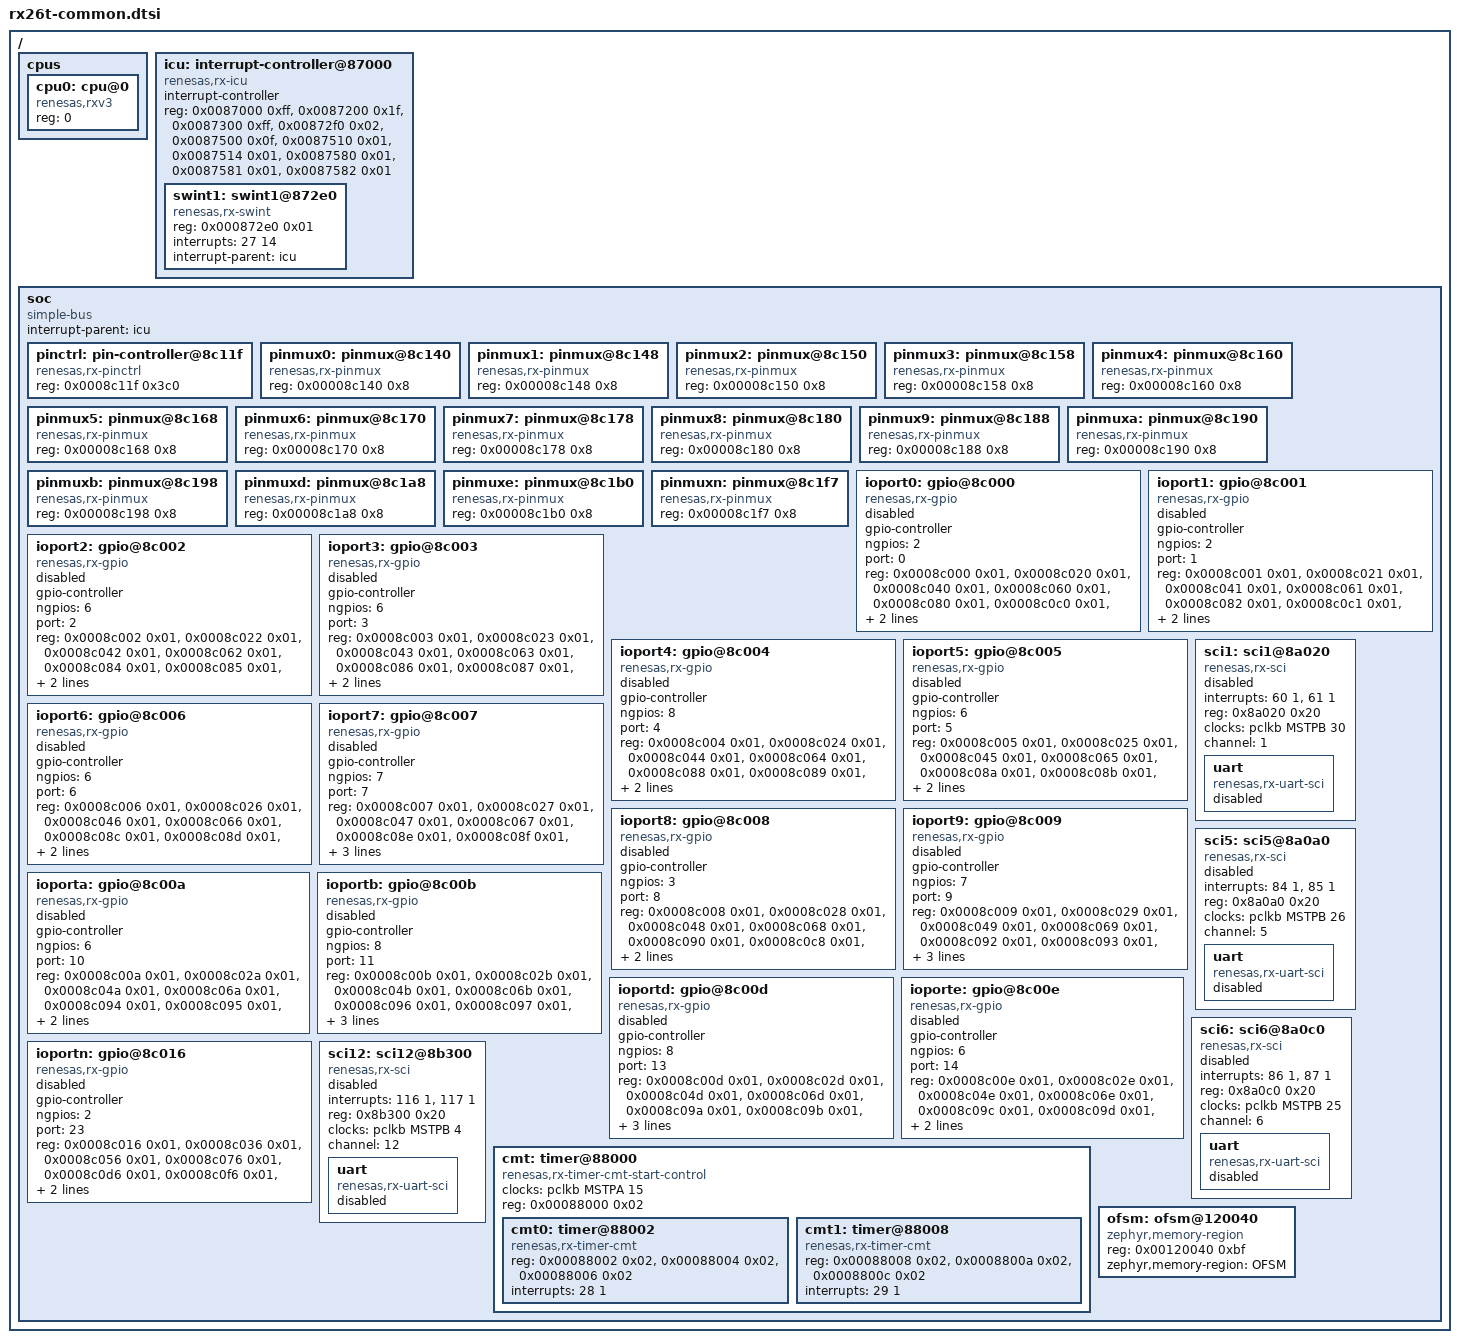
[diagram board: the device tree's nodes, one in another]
/*
 * Copyright (c) 2025 Renesas Electronics Corporation
 *
 * SPDX-License-Identifier: Apache-2.0
 */

/*
 * common device tree elements of all (currently supported) RX MCUs
 */

#include <mem.h>
#include <zephyr/dt-bindings/clock/rx_clock.h>
#include <zephyr/dt-bindings/pinctrl/renesas/pinctrl-rx.h>

/ {
	#address-cells = <1>;
	#size-cells = <1>;

	cpus {
		#address-cells = <1>;
		#size-cells = <0>;

		cpu0: cpu@0 {
			compatible = "renesas,rxv3";
			device_type = "cpu";
			reg = <0>;
			status = "okay";
		};
	};

	icu: interrupt-controller@87000 {
		#interrupt-cells = <2>;
		#address-cells = <1>;
		#size-cells = <1>;
		compatible = "renesas,rx-icu";
		interrupt-controller;
		reg = <0x0087000 0xff>,
		      <0x0087200 0x1f>,
		      <0x0087300 0xff>,
		      <0x00872f0 0x02>,
		      <0x0087500 0x0f>,
		      <0x0087510 0x01>,
		      <0x0087514 0x01>,
		      <0x0087580 0x01>,
		      <0x0087581 0x01>,
		      <0x0087582 0x01>;
		reg-names = "IR", "IER", "IPR", "FIR", "IRQCR", "IRQFLTE", "IRQFLTC0", "NMISR",
			    "NMIER", "NMICLR";

		swint1: swint1@872e0 {
			compatible = "renesas,rx-swint";
			reg = <0x000872e0 0x01>;
			interrupts = <27 14>;
			interrupt-parent = <&icu>;
			status = "okay";
		};
	};

	soc {
		#address-cells = <1>;
		#size-cells = <1>;
		device_type = "soc";
		compatible = "simple-bus";
		interrupt-parent = <&icu>;

		pinctrl: pin-controller@8c11f {
			compatible = "renesas,rx-pinctrl";
			reg = <0x0008c11f 0x3c0>;
			status = "okay";
		};

		pinmux0: pinmux@8c140 {
			compatible = "renesas,rx-pinmux";
			#pinmux-cells = <2>;
			reg = <0x00008c140 0x8>;
			status = "okay";
		};

		pinmux1: pinmux@8c148 {
			compatible = "renesas,rx-pinmux";
			#pinmux-cells = <2>;
			reg = <0x00008c148 0x8>;
			status = "okay";
		};

		pinmux2: pinmux@8c150 {
			compatible = "renesas,rx-pinmux";
			#pinmux-cells = <2>;
			reg = <0x00008c150 0x8>;
			status = "okay";
		};

		pinmux3: pinmux@8c158 {
			compatible = "renesas,rx-pinmux";
			#pinmux-cells = <2>;
			reg = <0x00008c158 0x8>;
			status = "okay";
		};

		pinmux4: pinmux@8c160 {
			compatible = "renesas,rx-pinmux";
			#pinmux-cells = <2>;
			reg = <0x00008c160 0x8>;
			status = "okay";
		};

		pinmux5: pinmux@8c168 {
			compatible = "renesas,rx-pinmux";
			#pinmux-cells = <2>;
			reg = <0x00008c168 0x8>;
			status = "okay";
		};

		pinmux6: pinmux@8c170 {
			compatible = "renesas,rx-pinmux";
			#pinmux-cells = <2>;
			reg = <0x00008c170 0x8>;
			status = "okay";
		};

		pinmux7: pinmux@8c178 {
			compatible = "renesas,rx-pinmux";
			#pinmux-cells = <2>;
			reg = <0x00008c178 0x8>;
			status = "okay";
		};

		pinmux8: pinmux@8c180 {
			compatible = "renesas,rx-pinmux";
			#pinmux-cells = <2>;
			reg = <0x00008c180 0x8>;
			status = "okay";
		};

		pinmux9: pinmux@8c188 {
			compatible = "renesas,rx-pinmux";
			#pinmux-cells = <2>;
			reg = <0x00008c188 0x8>;
			status = "okay";
		};

		pinmuxa: pinmux@8c190 {
			compatible = "renesas,rx-pinmux";
			#pinmux-cells = <2>;
			reg = <0x00008c190 0x8>;
			status = "okay";
		};

		pinmuxb: pinmux@8c198 {
			compatible = "renesas,rx-pinmux";
			#pinmux-cells = <2>;
			reg = <0x00008c198 0x8>;
			status = "okay";
		};

		pinmuxd: pinmux@8c1a8 {
			compatible = "renesas,rx-pinmux";
			#pinmux-cells = <2>;
			reg = <0x00008c1a8 0x8>;
			status = "okay";
		};

		pinmuxe: pinmux@8c1b0 {
			compatible = "renesas,rx-pinmux";
			#pinmux-cells = <2>;
			reg = <0x00008c1b0 0x8>;
			status = "okay";
		};

		pinmuxn: pinmux@8c1f7 {
			compatible = "renesas,rx-pinmux";
			#pinmux-cells = <2>;
			reg = <0x00008c1f7 0x8>;
			status = "okay";
		};

		ioport0: gpio@8c000 {
			compatible = "renesas,rx-gpio";
			gpio-controller;
			#gpio-cells = <0x02>;
			ngpios = <2>;
			port = <0>;
			reg = <0x0008c000 0x01>,
			      <0x0008c020 0x01>,
			      <0x0008c040 0x01>,
			      <0x0008c060 0x01>,
			      <0x0008c080 0x01>,
			      <0x0008c0c0 0x01>,
			      <0x0008c0e0 0x01>;
			reg-names = "PDR", "PODR", "PIDR", "PMR", "ODR0", "PCR", "DSCR";
			pinmux = <&pinmux0>;
			status = "disabled";
		};

		ioport1: gpio@8c001 {
			compatible = "renesas,rx-gpio";
			gpio-controller;
			#gpio-cells = <0x2>;
			ngpios = <2>;
			port = <1>;
			reg = <0x0008c001 0x01>,
			      <0x0008c021 0x01>,
			      <0x0008c041 0x01>,
			      <0x0008c061 0x01>,
			      <0x0008c082 0x01>,
			      <0x0008c0c1 0x01>,
			      <0x0008c0e1 0x01>;
			reg-names = "PDR", "PODR", "PIDR", "PMR", "ODR0", "PCR", "DSCR";
			pinmux = <&pinmux1>;
			status = "disabled";
		};

		ioport2: gpio@8c002 {
			compatible = "renesas,rx-gpio";
			gpio-controller;
			#gpio-cells = <0x2>;
			ngpios = <6>;
			port = <2>;
			reg = <0x0008c002 0x01>,
			      <0x0008c022 0x01>,
			      <0x0008c042 0x01>,
			      <0x0008c062 0x01>,
			      <0x0008c084 0x01>,
			      <0x0008c085 0x01>,
			      <0x0008c0c2 0x01>,
			      <0x0008c0e2 0x01>;
			reg-names = "PDR", "PODR", "PIDR", "PMR", "ODR0", "ODR1", "PCR", "DSCR";
			pinmux = <&pinmux2>;
			status = "disabled";
		};

		ioport3: gpio@8c003 {
			compatible = "renesas,rx-gpio";
			gpio-controller;
			#gpio-cells = <0x2>;
			ngpios = <6>;
			port = <3>;
			reg = <0x0008c003 0x01>,
			      <0x0008c023 0x01>,
			      <0x0008c043 0x01>,
			      <0x0008c063 0x01>,
			      <0x0008c086 0x01>,
			      <0x0008c087 0x01>,
			      <0x0008c0c3 0x01>,
			      <0x0008c0e3 0x01>;
			reg-names = "PDR", "PODR", "PIDR", "PMR", "ODR0", "ODR1", "PCR", "DSCR";
			pinmux = <&pinmux3>;
			status = "disabled";
		};

		ioport4: gpio@8c004 {
			compatible = "renesas,rx-gpio";
			gpio-controller;
			#gpio-cells = <0x2>;
			ngpios = <8>;
			port = <4>;
			reg = <0x0008c004 0x01>,
			      <0x0008c024 0x01>,
			      <0x0008c044 0x01>,
			      <0x0008c064 0x01>,
			      <0x0008c088 0x01>,
			      <0x0008c089 0x01>,
			      <0x0008c0c4 0x01>;
			reg-names = "PDR", "PODR", "PIDR", "PMR", "ODR0", "ODR1", "PCR";
			pinmux = <&pinmux4>;
			status = "disabled";
		};

		ioport5: gpio@8c005 {
			compatible = "renesas,rx-gpio";
			gpio-controller;
			#gpio-cells = <0x2>;
			ngpios = <6>;
			port = <5>;
			reg = <0x0008c005 0x01>,
			      <0x0008c025 0x01>,
			      <0x0008c045 0x01>,
			      <0x0008c065 0x01>,
			      <0x0008c08a 0x01>,
			      <0x0008c08b 0x01>,
			      <0x0008c0c5 0x01>;
			reg-names = "PDR", "PODR", "PIDR", "PMR", "ODR0", "ODR1", "PCR";
			pinmux = <&pinmux5>;
			status = "disabled";
		};

		ioport6: gpio@8c006 {
			compatible = "renesas,rx-gpio";
			gpio-controller;
			#gpio-cells = <0x2>;
			ngpios = <6>;
			port = <6>;
			reg = <0x0008c006 0x01>,
			      <0x0008c026 0x01>,
			      <0x0008c046 0x01>,
			      <0x0008c066 0x01>,
			      <0x0008c08c 0x01>,
			      <0x0008c08d 0x01>,
			      <0x0008c0c6 0x01>;
			reg-names = "PDR", "PODR", "PIDR", "PMR", "ODR0", "ODR1", "PCR";
			pinmux = <&pinmux5>;
			status = "disabled";
		};

		ioport7: gpio@8c007 {
			compatible = "renesas,rx-gpio";
			gpio-controller;
			#gpio-cells = <0x2>;
			ngpios = <7>;
			port = <7>;
			reg = <0x0008c007 0x01>,
			      <0x0008c027 0x01>,
			      <0x0008c047 0x01>,
			      <0x0008c067 0x01>,
			      <0x0008c08e 0x01>,
			      <0x0008c08f 0x01>,
			      <0x0008c0c7 0x01>,
			      <0x0008c0e7 0x01>,
			      <0x0008c12f 0x01>;
			reg-names = "PDR", "PODR", "PIDR", "PMR", "ODR0", "ODR1", "PCR",
				    "DSCR", "DSCR2";
			pinmux = <&pinmux7>;
			status = "disabled";
		};

		ioport8: gpio@8c008 {
			compatible = "renesas,rx-gpio";
			gpio-controller;
			#gpio-cells = <0x2>;
			ngpios = <3>;
			port = <8>;
			reg = <0x0008c008 0x01>,
			      <0x0008c028 0x01>,
			      <0x0008c048 0x01>,
			      <0x0008c068 0x01>,
			      <0x0008c090 0x01>,
			      <0x0008c0c8 0x01>,
			      <0x0008c0e8 0x01>,
			      <0x0008c130 0x01>;
			reg-names = "PDR", "PODR", "PIDR", "PMR", "ODR0", "PCR", "DSCR",
				    "DSCR2";
			pinmux = <&pinmux8>;
			status = "disabled";
		};

		ioport9: gpio@8c009 {
			compatible = "renesas,rx-gpio";
			gpio-controller;
			#gpio-cells = <0x2>;
			ngpios = <7>;
			port = <9>;
			reg = <0x0008c009 0x01>,
			      <0x0008c029 0x01>,
			      <0x0008c049 0x01>,
			      <0x0008c069 0x01>,
			      <0x0008c092 0x01>,
			      <0x0008c093 0x01>,
			      <0x0008c0c9 0x01>,
			      <0x0008c0e9 0x01>,
			      <0x0008c131 0x01>;
			reg-names = "PDR", "PODR", "PIDR", "PMR", "ODR0", "ODR1", "PCR",
				    "DSCR", "DSCR2";
			pinmux = <&pinmux9>;
			status = "disabled";
		};

		ioporta: gpio@8c00a {
			compatible = "renesas,rx-gpio";
			gpio-controller;
			#gpio-cells = <0x2>;
			ngpios = <6>;
			port = <10>;
			reg = <0x0008c00a 0x01>,
			      <0x0008c02a 0x01>,
			      <0x0008c04a 0x01>,
			      <0x0008c06a 0x01>,
			      <0x0008c094 0x01>,
			      <0x0008c095 0x01>,
			      <0x0008c0ca 0x01>,
			      <0x0008c0ea 0x01>;
			reg-names = "PDR", "PODR", "PIDR", "PMR", "ODR0", "ODR1",
				    "PCR", "DSCR";
			pinmux = <&pinmuxa>;
			status = "disabled";
		};

		ioportb: gpio@8c00b {
			compatible = "renesas,rx-gpio";
			gpio-controller;
			#gpio-cells = <0x2>;
			ngpios = <8>;
			port = <11>;
			reg = <0x0008c00b 0x01>,
			      <0x0008c02b 0x01>,
			      <0x0008c04b 0x01>,
			      <0x0008c06b 0x01>,
			      <0x0008c096 0x01>,
			      <0x0008c097 0x01>,
			      <0x0008c0cb 0x01>,
			      <0x0008c0eb 0x01>,
			      <0x0008c133 0x01>;
			reg-names = "PDR", "PODR", "PIDR", "PMR", "ODR0", "ODR1", "PCR",
				    "DSCR", "DSCR2";
			pinmux = <&pinmuxb>;
			status = "disabled";
		};

		ioportd: gpio@8c00d {
			compatible = "renesas,rx-gpio";
			gpio-controller;
			#gpio-cells = <0x2>;
			ngpios = <8>;
			port = <13>;
			reg = <0x0008c00d 0x01>,
			      <0x0008c02d 0x01>,
			      <0x0008c04d 0x01>,
			      <0x0008c06d 0x01>,
			      <0x0008c09a 0x01>,
			      <0x0008c09b 0x01>,
			      <0x0008c0cd 0x01>,
			      <0x0008c0ed 0x01>,
			      <0x0008c135 0x01>;
			reg-names = "PDR", "PODR", "PIDR", "PMR", "ODR0", "ODR1", "PCR",
				    "DSCR", "DSCR2";
			pinmux = <&pinmuxd>;
			status = "disabled";
		};

		ioporte: gpio@8c00e {
			compatible = "renesas,rx-gpio";
			gpio-controller;
			#gpio-cells = <0x2>;
			ngpios = <6>;
			port = <14>;
			reg = <0x0008c00e 0x01>,
			      <0x0008c02e 0x01>,
			      <0x0008c04e 0x01>,
			      <0x0008c06e 0x01>,
			      <0x0008c09c 0x01>,
			      <0x0008c09d 0x01>,
			      <0x0008c0ce 0x01>,
			      <0x0008c0ee 0x01>;
			reg-names = "PDR", "PODR", "PIDR", "PMR", "ODR0", "ODR1", "PCR", "DSCR";
			pinmux = <&pinmuxe>;
			status = "disabled";
		};

		ioportn: gpio@8c016 {
			compatible = "renesas,rx-gpio";
			gpio-controller;
			#gpio-cells = <0x2>;
			ngpios = <2>;
			port = <23>;
			reg = <0x0008c016 0x01>,
			      <0x0008c036 0x01>,
			      <0x0008c056 0x01>,
			      <0x0008c076 0x01>,
			      <0x0008c0d6 0x01>,
			      <0x0008c0f6 0x01>,
			      <0x0008c0ad 0x01>;
			reg-names = "PDR", "PODR", "PIDR", "PMR", "PCR", "DSCR", "ODR1";
			pinmux = <&pinmuxn>;
			status = "disabled";
		};

		sci1: sci1@8a020 {
			compatible = "renesas,rx-sci";
			interrupts = <60 1>, <61 1>;
			interrupt-names = "rxi", "txi";
			reg = <0x8a020 0x20>;
			clocks = <&pclkb MSTPB 30>;
			status = "disabled";
			channel = <1>;

			uart {
				compatible = "renesas,rx-uart-sci";
				status = "disabled";
			};
		};

		sci5: sci5@8a0a0 {
			compatible = "renesas,rx-sci";
			interrupts = <84 1>, <85 1>;
			interrupt-names = "rxi", "txi";
			reg = <0x8a0a0 0x20>;
			clocks = <&pclkb MSTPB 26>;
			status = "disabled";
			channel = <5>;

			uart {
				compatible = "renesas,rx-uart-sci";
				status = "disabled";
			};
		};

		sci6: sci6@8a0c0 {
			compatible = "renesas,rx-sci";
			interrupts = <86 1>, <87 1>;
			interrupt-names = "rxi", "txi";
			reg = <0x8a0c0 0x20>;
			clocks = <&pclkb MSTPB 25>;
			status = "disabled";
			channel = <6>;

			uart {
				compatible = "renesas,rx-uart-sci";
				status = "disabled";
			};
		};

		sci12: sci12@8b300 {
			compatible = "renesas,rx-sci";
			interrupts = <116 1>, <117 1>;
			interrupt-names = "rxi", "txi";
			reg = <0x8b300 0x20>;
			clocks = <&pclkb MSTPB 4>;
			status = "disabled";
			channel = <12>;

			uart {
				compatible = "renesas,rx-uart-sci";
				status = "disabled";
			};
		};

		cmt: timer@88000 {
			compatible = "renesas,rx-timer-cmt-start-control";
			#address-cells = <1>;
			#size-cells = <1>;
			clocks = <&pclkb MSTPA 15>;
			reg = <0x00088000 0x02>;
			reg-names = "CMSTR0";
			status = "okay";

			cmt0: timer@88002 {
				compatible = "renesas,rx-timer-cmt";
				#address-cells = <1>;
				#size-cells = <1>;
				reg = <0x00088002 0x02>,
				      <0x00088004 0x02>,
				      <0x00088006 0x02>;
				reg-names = "CMCR", "CMCNT", "CMCOR";
				interrupts = <28 1>;
				interrupt-names = "cmi";
				status = "okay";
			};

			cmt1: timer@88008 {
				compatible = "renesas,rx-timer-cmt";
				reg = <0x00088008 0x02>,
				      <0x0008800a 0x02>,
				      <0x0008800c 0x02>;
				reg-names = "CMCR", "CMCNT", "CMCOR";
				interrupts = <29 1>;
				interrupt-names = "cmi";
				status = "okay";
			};
		};

		ofsm: ofsm@120040 {
			compatible = "zephyr,memory-region";
			reg = <0x00120040 0xbf>;
			zephyr,memory-region = "OFSM";
			status = "okay";
		};
	};
};
